# RP2040 register map
Vendor: Raspberry Pi; File version: 0.1
CPU: CM0PLUS r0p1, little endian, MPU, no FPU, VTOR, 2 interrupt priority bits, 26 interrupts
Registers are 32-bit, read-write, reset 0x0 unless marked. A register's access mark holds for its fields unless they carry their own. Offsets are from the block's base; [hi:lo] are bit positions; {n}, {i} and the like mark numbered series.

## PPB
Base 0xE0000000
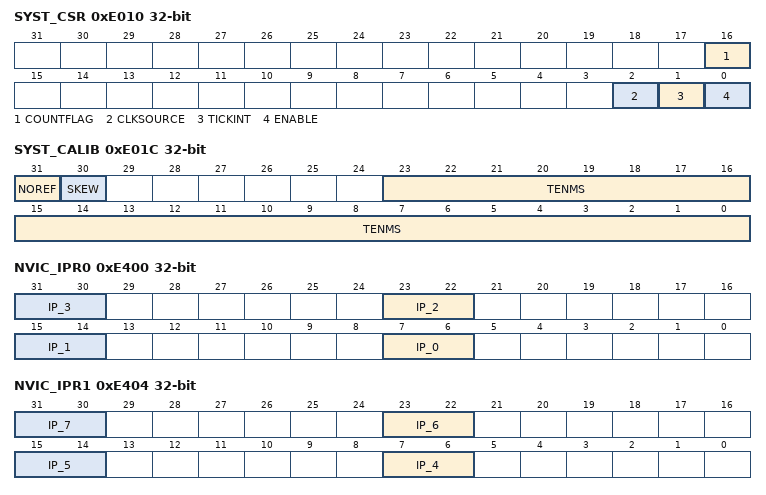
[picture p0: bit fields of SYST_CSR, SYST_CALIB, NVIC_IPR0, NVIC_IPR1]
0xE010 SYST_CSR access per field — Use the SysTick Control and Status Register to enable the SysTick features.
  [16] COUNTFLAG ro — Returns 1 if timer counted to 0 since last time this was read. Clears on read by application or debugger.
  [2] CLKSOURCE rw — SysTick clock source. Always reads as one if SYST_CALIB reports NOREF. Selects the SysTick timer clock source: 0 = External reference clock. 1 = Processor clock.
  [1] TICKINT rw — Enables SysTick exception request: 0 = Counting down to zero does not assert the SysTick exception request. 1 = Counting down to zero to asserts the SysTick exception request.
  [0] ENABLE rw — Enable SysTick counter: 0 = Counter disabled. 1 = Counter enabled.
0xE014 SYST_RVR — Use the SysTick Reload Value Register to specify the start value to load into the current value register when the counter reaches 0. It can be any value between 0 and 0x00FFFFFF. A start value of 0 is possible, but has no effect because the SysTick interrupt and COUNTFLAG are activated when counting from 1 to 0. The reset value of this register is UNKNOWN. To generate a multi-shot timer with a period of N processor clock cycles, use a RELOAD value of N-1. For example, if the SysTick interrupt is required every 100 clock pulses, set RELOAD to 99.
  [23:0] RELOAD — Value to load into the SysTick Current Value Register when the counter reaches 0.
0xE018 SYST_CVR — Use the SysTick Current Value Register to find the current value in the register. The reset value of this register is UNKNOWN.
  [23:0] CURRENT — Reads return the current value of the SysTick counter. This register is write-clear. Writing to it with any value clears the register to 0. Clearing this register also clears the COUNTFLAG bit of the SysTick Control and Status Register.
0xE01C SYST_CALIB ro — Use the SysTick Calibration Value Register to enable software to scale to any required speed using divide and multiply.
  [31] NOREF — If reads as 1, the Reference clock is not provided - the CLKSOURCE bit of the SysTick Control and Status register will be forced to 1 and cannot be cleared to 0.
  [30] SKEW — If reads as 1, the calibration value for 10ms is inexact (due to clock frequency).
  [23:0] TENMS — An optional Reload value to be used for 10ms (100Hz) timing, subject to system clock skew errors. If the value reads as 0, the calibration value is not known.
0xE100 NVIC_ISER — Use the Interrupt Set-Enable Register to enable interrupts and determine which interrupts are currently enabled. If a pending interrupt is enabled, the NVIC activates the interrupt based on its priority. If an interrupt is not enabled, asserting its interrupt signal changes the interrupt state to pending, but the NVIC never activates the interrupt, regardless of its priority.
  [31:0] SETENA — Interrupt set-enable bits. Write: 0 = No effect. 1 = Enable interrupt. Read: 0 = Interrupt disabled. 1 = Interrupt enabled.
0xE180 NVIC_ICER — Use the Interrupt Clear-Enable Registers to disable interrupts and determine which interrupts are currently enabled.
  [31:0] CLRENA — Interrupt clear-enable bits. Write: 0 = No effect. 1 = Disable interrupt. Read: 0 = Interrupt disabled. 1 = Interrupt enabled.
0xE200 NVIC_ISPR — The NVIC_ISPR forces interrupts into the pending state, and shows which interrupts are pending.
  [31:0] SETPEND — Interrupt set-pending bits. Write: 0 = No effect. 1 = Changes interrupt state to pending. Read: 0 = Interrupt is not pending. 1 = Interrupt is pending. Note: Writing 1 to the NVIC_ISPR bit corresponding to: An interrupt that is pending has no effect. A disabled interrupt sets the state of that interrupt to pending.
0xE280 NVIC_ICPR — Use the Interrupt Clear-Pending Register to clear pending interrupts and determine which interrupts are currently pending.
  [31:0] CLRPEND — Interrupt clear-pending bits. Write: 0 = No effect. 1 = Removes pending state and interrupt. Read: 0 = Interrupt is not pending. 1 = Interrupt is pending.
0xE400 NVIC_IPR0 — Use the Interrupt Priority Registers to assign a priority from 0 to 3 to each of the available interrupts. 0 is the highest priority, and 3 is the lowest. Note: Writing 1 to an NVIC_ICPR bit does not affect the active state of the corresponding interrupt. These registers are only word-accessible
  [8n+7:8n+6] IP_{n} (n=0..3) — Priority of interrupt {n}
0xE404 NVIC_IPR1 — Use the Interrupt Priority Registers to assign a priority from 0 to 3 to each of the available interrupts. 0 is the highest priority, and 3 is the lowest.
  [8n-25:8n-26] IP_{n} (n=4..7) — Priority of interrupt {n}
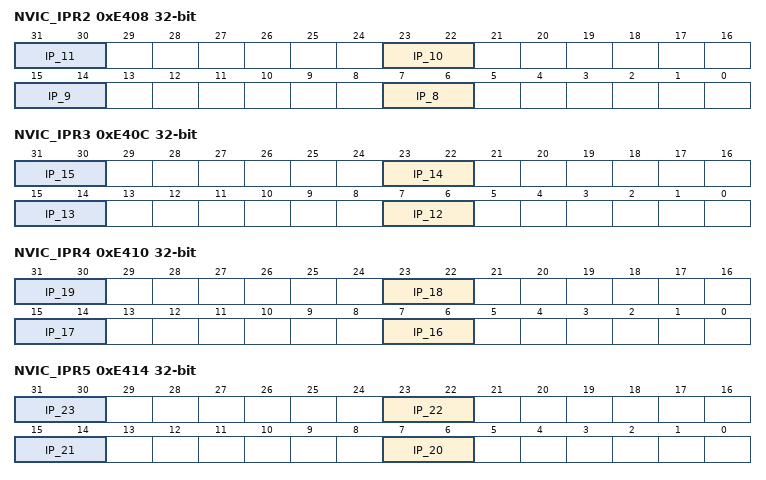
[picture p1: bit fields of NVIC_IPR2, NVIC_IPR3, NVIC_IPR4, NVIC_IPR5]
0xE408 NVIC_IPR2 — Use the Interrupt Priority Registers to assign a priority from 0 to 3 to each of the available interrupts. 0 is the highest priority, and 3 is the lowest.
  [8n-57:8n-58] IP_{n} (n=8..11) — Priority of interrupt {n}
0xE40C NVIC_IPR3 — Use the Interrupt Priority Registers to assign a priority from 0 to 3 to each of the available interrupts. 0 is the highest priority, and 3 is the lowest.
  [8n-89:8n-90] IP_{n} (n=12..15) — Priority of interrupt {n}
0xE410 NVIC_IPR4 — Use the Interrupt Priority Registers to assign a priority from 0 to 3 to each of the available interrupts. 0 is the highest priority, and 3 is the lowest.
  [8n-121:8n-122] IP_{n} (n=16..19) — Priority of interrupt {n}
0xE414 NVIC_IPR5 — Use the Interrupt Priority Registers to assign a priority from 0 to 3 to each of the available interrupts. 0 is the highest priority, and 3 is the lowest.
  [8n-153:8n-154] IP_{n} (n=20..23) — Priority of interrupt {n}
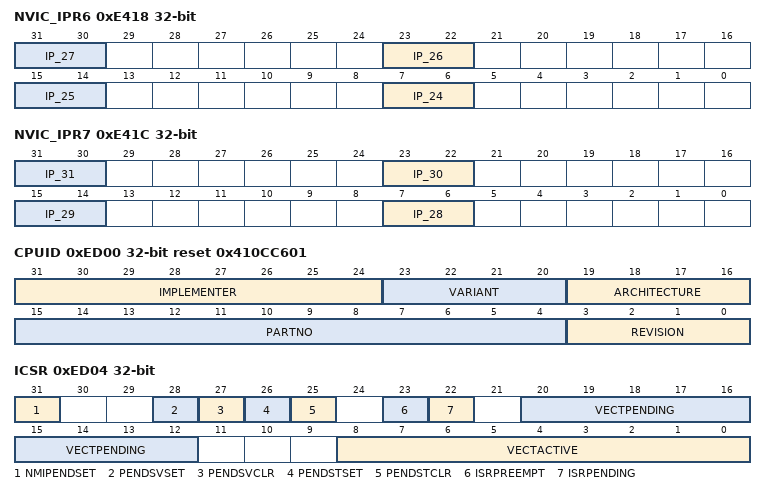
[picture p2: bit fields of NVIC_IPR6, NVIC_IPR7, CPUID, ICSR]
0xE418 NVIC_IPR6 — Use the Interrupt Priority Registers to assign a priority from 0 to 3 to each of the available interrupts. 0 is the highest priority, and 3 is the lowest.
  [8n-185:8n-186] IP_{n} (n=24..27) — Priority of interrupt {n}
0xE41C NVIC_IPR7 — Use the Interrupt Priority Registers to assign a priority from 0 to 3 to each of the available interrupts. 0 is the highest priority, and 3 is the lowest.
  [8n-217:8n-218] IP_{n} (n=28..31) — Priority of interrupt {n}
0xED00 CPUID ro reset 0x410CC601 — Read the CPU ID Base Register to determine: the ID number of the processor core, the version number of the processor core, the implementation details of the processor core.
  [31:24] IMPLEMENTER — Implementor code: 0x41 = ARM
  [23:20] VARIANT — Major revision number n in the rnpm revision status: 0x0 = Revision 0.
  [19:16] ARCHITECTURE — Constant that defines the architecture of the processor: 0xC = ARMv6-M architecture.
  [15:4] PARTNO — Number of processor within family: 0xC60 = Cortex-M0+
  [3:0] REVISION — Minor revision number m in the rnpm revision status: 0x1 = Patch 1.
0xED04 ICSR access per field — Use the Interrupt Control State Register to set a pending Non-Maskable Interrupt (NMI), set or clear a pending PendSV, set or clear a pending SysTick, check for pending exceptions, check the vector number of the highest priority pended exception, check the vector number of the active exception.
  [31] NMIPENDSET rw — Setting this bit will activate an NMI. Since NMI is the highest priority exception, it will activate as soon as it is registered. NMI set-pending bit. Write: 0 = No effect. 1 = Changes NMI exception state to pending. Read: 0 = NMI exception is not pending. 1 = NMI exception is pending. Because NMI is the highest-priority exception, normally the processor enters the NMI exception handler as soon as it detects a write of 1 to this bit. Entering the handler then clears this bit to 0. This means a read of this bit by the NMI exception handler returns 1 only if the. NMI signal is reasserted while the processor is executing that handler.
  [28] PENDSVSET rw — PendSV set-pending bit. Write: 0 = No effect. 1 = Changes PendSV exception state to pending. Read: 0 = PendSV exception is not pending. 1 = PendSV exception is pending. Writing 1 to this bit is the only way to set the PendSV exception state to pending.
  [27] PENDSVCLR rw — PendSV clear-pending bit. Write: 0 = No effect. 1 = Removes the pending state from the PendSV exception.
  [26] PENDSTSET rw — SysTick exception set-pending bit. Write: 0 = No effect. 1 = Changes SysTick exception state to pending. Read: 0 = SysTick exception is not pending. 1 = SysTick exception is pending.
  [25] PENDSTCLR rw — SysTick exception clear-pending bit. Write: 0 = No effect. 1 = Removes the pending state from the SysTick exception. This bit is WO. On a register read its value is Unknown.
  [23] ISRPREEMPT ro — The system can only access this bit when the core is halted. It indicates that a pending interrupt is to be taken in the next running cycle. If C_MASKINTS is clear in the Debug Halting Control and Status Register, the interrupt is serviced.
  [22] ISRPENDING ro — External interrupt pending flag
  [20:12] VECTPENDING ro — Indicates the exception number for the highest priority pending exception: 0 = no pending exceptions. Non zero = The pending state includes the effect of memory-mapped enable and mask registers. It does not include the PRIMASK special-purpose register qualifier.
  [8:0] VECTACTIVE ro — Active exception number field. Reset clears the VECTACTIVE field.
0xED08 VTOR — The VTOR holds the vector table offset address.
  [31:8] TBLOFF — Bits [31:8] of the indicate the vector table offset address.
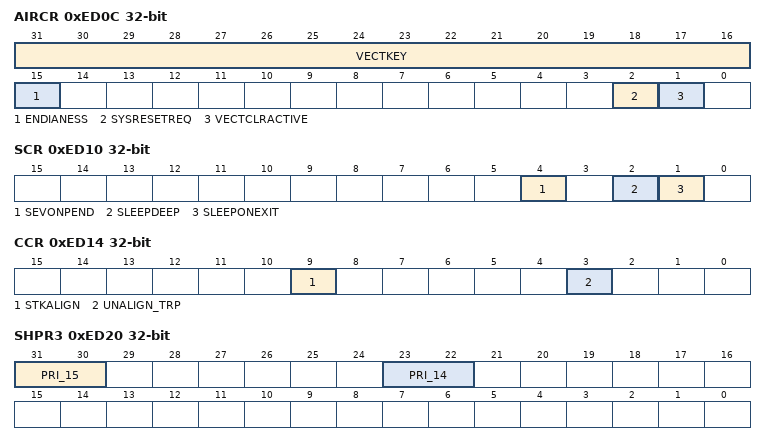
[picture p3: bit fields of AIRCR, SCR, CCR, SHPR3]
0xED0C AIRCR access per field — Use the Application Interrupt and Reset Control Register to: determine data endianness, clear all active state information from debug halt mode, request a system reset.
  [31:16] VECTKEY rw — Register key: Reads as Unknown. On writes, write 0x05FA to VECTKEY, otherwise the write is ignored.
  [15] ENDIANESS ro — Data endianness implemented: 0 = Little-endian.
  [2] SYSRESETREQ rw — Writing 1 to this bit causes the SYSRESETREQ signal to the outer system to be asserted to request a reset. The intention is to force a large system reset of all major components except for debug. The C_HALT bit in the DHCSR is cleared as a result of the system reset requested. The debugger does not lose contact with the device.
  [1] VECTCLRACTIVE rw — Clears all active state information for fixed and configurable exceptions. This bit: is self-clearing, can only be set by the DAP when the core is halted. When set: clears all active exception status of the processor, forces a return to Thread mode, forces an IPSR of 0. A debugger must re-initialize the stack.
0xED10 SCR — System Control Register. Use the System Control Register for power-management functions: signal to the system when the processor can enter a low power state, control how the processor enters and exits low power states.
  [4] SEVONPEND — Send Event on Pending bit: 0 = Only enabled interrupts or events can wakeup the processor, disabled interrupts are excluded. 1 = Enabled events and all interrupts, including disabled interrupts, can wakeup the processor. When an event or interrupt becomes pending, the event signal wakes up the processor from WFE. If the processor is not waiting for an event, the event is registered and affects the next WFE. The processor also wakes up on execution of an SEV instruction or an external event.
  [2] SLEEPDEEP — Controls whether the processor uses sleep or deep sleep as its low power mode: 0 = Sleep. 1 = Deep sleep.
  [1] SLEEPONEXIT — Indicates sleep-on-exit when returning from Handler mode to Thread mode: 0 = Do not sleep when returning to Thread mode. 1 = Enter sleep, or deep sleep, on return from an ISR to Thread mode. Setting this bit to 1 enables an interrupt driven application to avoid returning to an empty main application.
0xED14 CCR ro — The Configuration and Control Register permanently enables stack alignment and causes unaligned accesses to result in a Hard Fault.
  [9] STKALIGN — Always reads as one, indicates 8-byte stack alignment on exception entry. On exception entry, the processor uses bit[9] of the stacked PSR to indicate the stack alignment. On return from the exception it uses this stacked bit to restore the correct stack alignment.
  [3] UNALIGN_TRP — Always reads as one, indicates that all unaligned accesses generate a HardFault.
0xED1C SHPR2 — System handlers are a special class of exception handler that can have their priority set to any of the priority levels. Use the System Handler Priority Register 2 to set the priority of SVCall.
  [31:30] PRI_11 — Priority of system handler 11, SVCall
0xED20 SHPR3 — System handlers are a special class of exception handler that can have their priority set to any of the priority levels. Use the System Handler Priority Register 3 to set the priority of PendSV and SysTick.
  [31:30] PRI_15 — Priority of system handler 15, SysTick
  [23:22] PRI_14 — Priority of system handler 14, PendSV
0xED24 SHCSR — Use the System Handler Control and State Register to determine or clear the pending status of SVCall.
  [15] SVCALLPENDED — Reads as 1 if SVCall is Pending. Write 1 to set pending SVCall, write 0 to clear pending SVCall.
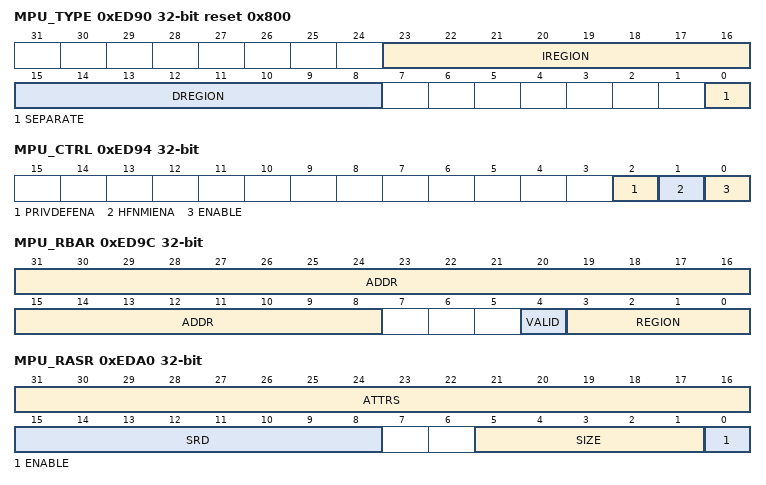
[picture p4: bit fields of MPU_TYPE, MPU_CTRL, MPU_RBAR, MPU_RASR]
0xED90 MPU_TYPE ro reset 0x800 — Read the MPU Type Register to determine if the processor implements an MPU, and how many regions the MPU supports.
  [23:16] IREGION — Instruction region. Reads as zero as ARMv6-M only supports a unified MPU.
  [15:8] DREGION — Number of regions supported by the MPU.
  [0] SEPARATE — Indicates support for separate instruction and data address maps. Reads as 0 as ARMv6-M only supports a unified MPU.
0xED94 MPU_CTRL — Use the MPU Control Register to enable and disable the MPU, and to control whether the default memory map is enabled as a background region for privileged accesses, and whether the MPU is enabled for HardFaults and NMIs.
  [2] PRIVDEFENA — Controls whether the default memory map is enabled as a background region for privileged accesses. This bit is ignored when ENABLE is clear. 0 = If the MPU is enabled, disables use of the default memory map. Any memory access to a location not covered by any enabled region causes a fault. 1 = If the MPU is enabled, enables use of the default memory map as a background region for privileged software accesses. When enabled, the background region acts as if it is region number -1. Any region that is defined and enabled has priority over this default map.
  [1] HFNMIENA — Controls the use of the MPU for HardFaults and NMIs. Setting this bit when ENABLE is clear results in UNPREDICTABLE behaviour. When the MPU is enabled: 0 = MPU is disabled during HardFault and NMI handlers, regardless of the value of the ENABLE bit. 1 = the MPU is enabled during HardFault and NMI handlers.
  [0] ENABLE — Enables the MPU. If the MPU is disabled, privileged and unprivileged accesses use the default memory map. 0 = MPU disabled. 1 = MPU enabled.
0xED98 MPU_RNR — Use the MPU Region Number Register to select the region currently accessed by MPU_RBAR and MPU_RASR.
  [3:0] REGION — Indicates the MPU region referenced by the MPU_RBAR and MPU_RASR registers. The MPU supports 8 memory regions, so the permitted values of this field are 0-7.
0xED9C MPU_RBAR — Read the MPU Region Base Address Register to determine the base address of the region identified by MPU_RNR. Write to update the base address of said region or that of a specified region, with whose number MPU_RNR will also be updated.
  [31:8] ADDR — Base address of the region.
  [4] VALID — On writes, indicates whether the write must update the base address of the region identified by the REGION field, updating the MPU_RNR to indicate this new region. Write: 0 = MPU_RNR not changed, and the processor: Updates the base address for the region specified in the MPU_RNR. Ignores the value of the REGION field. 1 = The processor: Updates the value of the MPU_RNR to the value of the REGION field. Updates the base address for the region specified in the REGION field. Always reads as zero.
  [3:0] REGION — On writes, specifies the number of the region whose base address to update provided VALID is set written as 1. On reads, returns bits [3:0] of MPU_RNR.
0xEDA0 MPU_RASR — Use the MPU Region Attribute and Size Register to define the size, access behaviour and memory type of the region identified by MPU_RNR, and enable that region.
  [31:16] ATTRS — The MPU Region Attribute field. Use to define the region attribute control. 28 = XN: Instruction access disable bit: 0 = Instruction fetches enabled. 1 = Instruction fetches disabled. 26:24 = AP: Access permission field. 18 = S: Shareable bit. 17 = C: Cacheable bit. 16 = B: Bufferable bit
  [15:8] SRD — Subregion Disable. For regions of 256 bytes or larger, each bit of this field controls whether one of the eight equal subregions is enabled.
  [5:1] SIZE — Indicates the region size. Region size in bytes = 2^(SIZE+1). The minimum permitted value is 7 (b00111) = 256Bytes
  [0] ENABLE — Enables the region.

## Notices in the file
Copyright (c) 2020 Raspberry Pi (Trading) Ltd.
SPDX-License-Identifier: BSD-3-Clause
